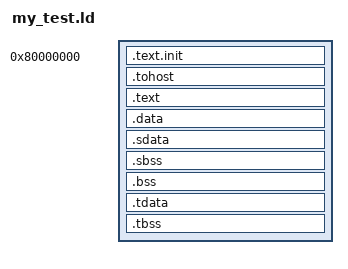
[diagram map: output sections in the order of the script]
/*======================================================================*/
/* Proxy kernel linker script                                           */
/*======================================================================*/
/* This is the linker script used when building the proxy kernel. */

/*----------------------------------------------------------------------*/
/* Setup                                                                */
/*----------------------------------------------------------------------*/

/* The OUTPUT_ARCH command specifies the machine architecture where the
   argument is one of the names used in the BFD library. More
   specifically one of the entries in bfd/cpu-mips.c */

OUTPUT_ARCH( "riscv" )
ENTRY(_start)

/*----------------------------------------------------------------------*/
/* Sections                                                             */
/*----------------------------------------------------------------------*/

SECTIONS
{

  /* text: test code section */
  . = 0x80000000;
  .text.init : { *(.text.init) }

  /* Set the starting address of .rodata segment */
  /* . = ALIGN(0x1000); */
  /* .rodata : { *(.rodata) } */

  . = ALIGN(0x2000);
  .tohost : { *(.tohost) }

  .text : { *(.text) }

  /* data segment */
  .data : { *(.data) }

  .sdata : {
    __global_pointer$ = . + 0x800;
    *(.srodata.cst16) *(.srodata.cst8) *(.srodata.cst4) *(.srodata.cst2) *(.srodata*)
    *(.sdata .sdata.* .gnu.linkonce.s.*)
  }

  /* bss segment */
  .sbss : {
    *(.sbss .sbss.* .gnu.linkonce.sb.*)
    *(.scommon)
  }
  .bss : { *(.bss) }

  /* thread-local data segment */
  .tdata :
  {
    _tls_data = .;
    *(.tdata.begin)
    *(.tdata)
    *(.tdata.end)
  }
  .tbss :
  {
    *(.tbss)
    *(.tbss.end)
  }

  /* customized define for tiny-malloc function */
  /* note : the DRAM address in RoCC is 0x8000_0000 to  0x9000_0000*/
  __malloc_start = .;
  __malloc_len = 0x03000000;
  . = . + __malloc_len;

  /* End of uninitalized data segement */
  end = .;
  . = . + 0x00001000;
  
  _end = .;
}
